# ble_rfcore_mdm_secure register map
Vendor: Texas Instruments
Registers are 32-bit, access per field, reset 0x0 unless marked. A register's access mark holds for its fields unless they carry their own. Offsets are as the file gives them; [hi:lo] are bit positions; {n}, {i} and the like mark numbered series; 'fields as' and 'values as' point back to an identical list.

## ble_rfcore_mdm_secure (part 2 of 2)
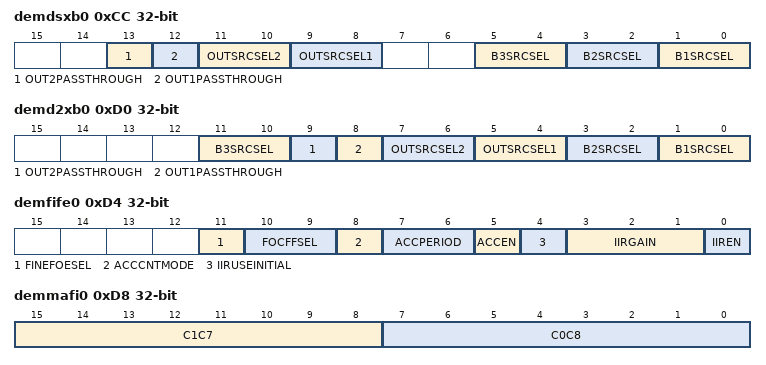
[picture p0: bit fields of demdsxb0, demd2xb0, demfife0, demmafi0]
0xCC demdsxb0 — Demodulator Decode Stage Crossbar Register 0
  [13] OUT2PASSTHROUGH rw — Crossbar output #2 is direct passthrough of the crossbar input
  [12] OUT1PASSTHROUGH rw — Crossbar output #1 is direct passthrough of the crossbar input
  [11:10] OUTSRCSEL2 rw — Source select XBAR output, branch 1 (baud branch)
    0=FIFE (Source is fine frequency offset estimator (FIFE)); 1=MAFI (Source is matched filter (MAFI)); 2=C1BE (Source is 1-bit correlation engine (C1BE))
  [9:8] OUTSRCSEL1 rw — Source select for XBAR output, branch 2 (flushed branch)
    values as OUTSRCSEL2
  [5:4] B3SRCSEL rw — Source select for C1BE (XBAR block #3)
    0=INPUT (Source is crossbar main input); 1=FIFE (Source is fine frequency offset estimator (FIFE)); 2=MAFI (Source is matched filter (MAFI))
  [3:2] B2SRCSEL rw — Source select for MAFI (XBAR block #2)
    0=INPUT (Source is crossbar main input); 1=FIFE (Source is fine frequency offset estimator (FIFE)); 2=C1BE (Source is 1-bit correlation engine (C1BE))
  [1:0] B1SRCSEL rw — Source select for FIFE (XBAR block #1)
    0=INPUT (Source is crossbar main input); 1=MAFI (Source is matched filter (MAFI)); 2=C1BE (Source is 1-bit correlation engine (C1BE))
0xD0 demd2xb0 — Demodulator Decode Stage Second Crossbar Register 0
  [11:10] B3SRCSEL rw — Source select for PDIF2 (XBAR block #3)
    0=INPUT (Source is crossbar main input); 1=MAFC (Source is manual frequency compensation (MAFC)); 2=STIM (Source is symbol timing (STIM))
  [9] OUT2PASSTHROUGH rw — Crossbar output #2 is direct passthrough of the crossbar input
  [8] OUT1PASSTHROUGH rw — Crossbar output #1 is direct passthrough of the crossbar input
  [7:6] OUTSRCSEL2 rw — Source select XBAR output, branch 1 (towards MLSE)
    0=MAFC (Source is manual frequency compensation (MAFC)); 1=STIM (Source is symbol timing (STIM)); 2=PDIF2 (Source is secondary PDIF module (PDIF2))
  [5:4] OUTSRCSEL1 rw — Source select for XBAR output, branch 2 (towards SOFD)
    values as OUTSRCSEL2
  [3:2] B2SRCSEL rw — Source select for STIM (XBAR block #2)
    0=INPUT (Source is crossbar main input); 1=MAFC (Source is manual frequency compensation (MAFC)); 2=PDIF2 (Source is secondary PDIF module (PDIF2))
  [1:0] B1SRCSEL rw — Source select for MAFC (XBAR block #1)
    0=INPUT (Source is crossbar main input); 1=STIM (Source is symbol timing (STIM)); 2=PDIF2 (Source is secondary PDIF module (PDIF2))
0xD4 demfife0 — Demodulator Fine Frequency Offset Estimator Register 0
  [11] FINEFOESEL rw — Select which estimator to show as readable output
    0=IIR (Latest IIR estimate); 1=ACC (Latest accumulator estimate)
  [10:9] FOCFFSEL rw — Select which estimate source to be used in feed-forward compensation point
    0=IIR (Compensate with latest IIR estimate); 1=ACC (Compensate with latest accumulator estimate); 2=MANUAL (Use programmable manual value from register bank. (Note: an input register is not implemented, so the manual compensation value is tied to '0'))
  [8] ACCCNTMODE rw — Accumulator estimator mode
    0=SINGLE (Generate a single frequency offset estimate only, then stop); 1=CONT (Generate new frequency offset estimates continuously)
  [7:6] ACCPERIOD rw — Integration period for accumulator
    0=PER64 (64 samples); 1=PER128 (128 samples); 2=PER256 (256 samples); 3=PER512 (512 samples)
  [5] ACCEN rw — Enable accumulator based frequency offset estimator inside FIFE
    0=DIS (Disable accumulator estimator); 1=EN (Enable accumulator estimator)
  [4] IIRUSEINITIAL rw — When enabled, a configurable value is loaded to initialize IIR filter when FIFE estimator is re-initialized.
    0=DIS (Initialize IIR filter with value zero); 1=EN (Use the manual compensation value in DEMFIFE1 for initialization)
  [3:1] IIRGAIN rw — Adjust first-order IIR filter adaptation which controls filter bandwidth
    0=OFF (Filter disabled); 1=DIV16 (Use 1/16 IIR adaptation); 2=DIV32 (Use 1/32 IIR adaptation); 3=DIV64 (Use 1/64 IIR adaptation); 4=DIV128 (Use 1/128 IIR adaptation); 5=DIV256 (Use 1/256 IIR adaptation); 6=DIV512 (Use 1/512 IIR adaptation); 7=DIV1024 (Use 1/1024 IIR adaptation)
  [0] IIREN rw — Enable first-order IIR filter based freq offset estimator inside FIFE
    0=DIS (Disable IIR estimator); 1=EN (Enable IIR estimator)
0xD8 demmafi0 — Demodulator Matched Filter Register 0
  [15:8] C1C7 rw — Filter coefficient c1 (and c7)
  [7:0] C0C8 rw — Filter coefficient c0 (and c8)
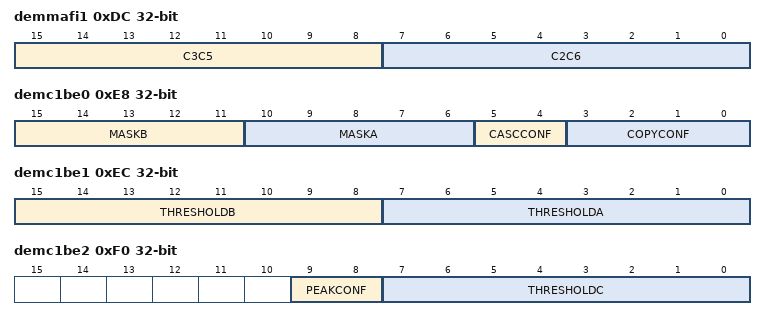
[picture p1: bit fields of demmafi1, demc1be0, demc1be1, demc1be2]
0xDC demmafi1 — Demodulator Matched Filter Register 1
  [15:8] C3C5 rw — Filter coefficient c3 (and c5)
  [7:0] C2C6 rw — Filter coefficient c2 (and c6)
0xE0 demmafi2 — Demodulator Matched Filter Register 2
  [8:0] C4 rw — Filter coefficient c4. The matched filter will have unity gain when the sum of all coefficients c0 to c8 equals 512.
0xE4 demmafi3 — Demodulator Matched Filter Register 3
  [8:0] K rw — Output level adjustment. Adjusting LSB of k will adjust LSB of matched filter output accordingly.
0xE8 demc1be0 — Demodulator Correlator 1-bit Engine Register 0
  [15:11] MASKB rw — Mask for correlator B to select the correlator length to use. The number specifies number of nibbles (i.e. 4-bit block, which typically corresponds to one symbol) of the correlator holding the oldest samples that will be ignored in computations. When set to zero, the full 128 sample (=32 symbol) correlator length will be used.
  [10:6] MASKA rw — Mask for correlator A to select the correlator length to use. The number specifies number of nibbles (i.e. 4-bit block, which typically corresponds to one symbol) of the correlator holding the oldest samples that will be ignored in computations. When set to zero, the full 128 sample (=32 symbol) correlator length will be used.
  [5:4] CASCCONF rw — Correlator cascade configuration
    0=SINGLE (Correlator B not used); 1=SERIAL (Connect correlators in series (A -> B)); 2=PARALLEL (Connect correlators in parallel)
  [3:0] COPYCONF rw — Control auto copy of contents from corr A to corr B
0xEC demc1be1 — Demodulator Correlator 1-bit Engine Register 1
  [15:8] THRESHOLDB rw — Correlation threshold value for correlator B
  [7:0] THRESHOLDA rw — Correlation threshold value for correlator A
0xF0 demc1be2 — Demodulator Correlator 1-bit Engine Register 2
  [9:8] PEAKCONF rw — Configuration to control peak event generation (applies to correlators A, B, D, E)
    0=THRESH (Trigger peak event on all peaks above threshold); 1=BEST (Trigger peak event only if peak is highest in correlator since search start); 2=BESTAB (Trigger peak event for combined highest peak search for corr "A and B" and "D and E" in pairs)
  [7:0] THRESHOLDC rw — Correlation threshold value for correlator C (corr C is A+B concatenated)
0xF4 demc1be10 — Demodulator Correlator 1-bit Engine Control
  [14:13] PEAKCONF_C rw — Configuration to control peak event generation for correlator C
    0=THRESH (Trigger peak event on all peaks above threshold); 1=BEST (Trigger peak event only if peak is highest in correlator since search start); 2=BESTAB (Trigger peak event for combined highest peak search for corr C and F)
0xF8 mdmsync0 — Modem Sync Word Register 0
  [15:0] SWA15C0 rw — Sync word A bits 15:0. Sync words shorter than 32 bits must be stored as most signicant bits of sync word A. The sync word is expected to be transmitted/received in lsb to msb order.
0xFC mdmsync1 — Modem Sync Word Register 1
  [15:0] SWA31C16 rw — Sync word A bits 31:16. Sync words shorter than 32 bits must be stored as most significant bits of sync word A. The sync word is expected to be transmitted/received in lsb to msb order.
0x100 mdmsync2 — Modem Sync Word Register 2
  [15:0] SWB15C0 rw — Sync word B bits 15:0. Sync words shorter than 32 bits must be stored as most significant bits of sync word B. The sync word is expected to be transmitted/received in lsb to msb order.
0x104 mdmsync3 — Modem Sync Word Register 3
  [15:0] SWB31C16 rw — Sync word B bits 31:16. Sync words shorter than 32 bits must be stored as most significant bits of sync word B. The sync word is expected to be transmitted/received in lsb to msb order.
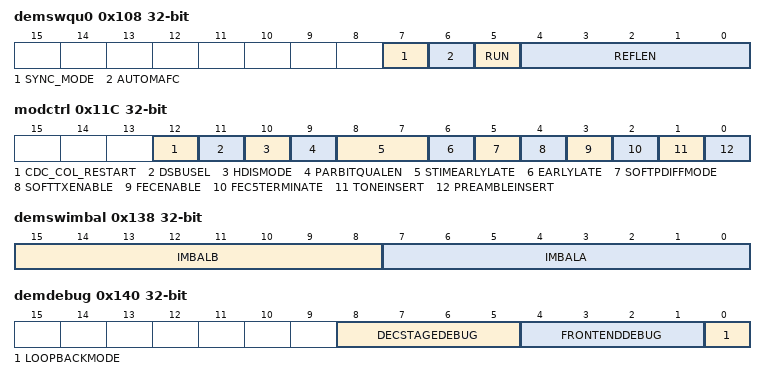
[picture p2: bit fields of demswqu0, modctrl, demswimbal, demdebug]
0x108 demswqu0 — Demodulator Sync Word Qualifier Register 0
  [7] SYNC_MODE rw — 0: Search for A and B in parallell
  [6] AUTOMAFC rw — Let sync word qualifier automatically control the manual frequency offset compensation (MAFC) block when it is running
    0=DIS (Keep manual control over MAFC); 1=EN (Give control to sync word qualifier)
  [5] RUN rw — Start/stop sync word qualifier
  [4:0] REFLEN rw — Bit length of sync word qualifier reference vector, constituted by (reflen + 1) most significant bits of sync word A and/or B.
0x10C demc1beref0 — Correlator reference register 0
  [15:0] CAR15C0 rw — Corr A reference bits 15:0.
0x110 demc1beref1 — Correlator reference register 1
  [15:0] CAR31C16 rw — Corr A reference bits 31:16
0x114 demc1beref2 — Correlator reference register 2
  [15:0] CBR15C0 rw — Corr B reference bits 15:0.
0x118 demc1beref3 — Correlator reference register 3
  [15:0] CBR31C16 rw — Corr B reference bits 31:16
0x11C modctrl — Dynamic Modem Control Signals from MCE
  [12] CDC_COL_RESTART rw — Collision restart for CDC FIFO
  [11] DSBUSEL rw — Select DSBU input source
  [10] HDISMODE rw — Enable Hilbert discriminator mode for data descicion
  [9] PARBITQUALEN rw — Enable Parallel Bit Qualifier (read DEMC1BEA)
  [8:7] STIMEARLYLATE rw — Controls STIM module for early/late modes
    0=NORMAL (Normal Mode); 1=LATE (STIM starts late); 2=EARLY (STIM starts early)
  [6] EARLYLATE rw — Set the C1BE in special early/late mode
  [5] SOFTPDIFFMODE rw — Enable Soft PDIFF mode for RX
  [4] SOFTTXENABLE rw — Enable SOFT TX mode, controlled via MODSOFTTX
  [3] FECENABLE rw — Global FEC modes enable
  [2] FEC5TERMINATE rw — Goes into termination mode in 5Mbps TX FEC
  [1] TONEINSERT rw — Inserts a tone
  [0] PREAMBLEINSERT rw — Inserts preamble
0x120 modpreamble — Dynamic Modulator Preamble Register
  [15:0] WORD rw — 16 bit preamble word pattern. The LSB is transmitted first.
0x124 demfidc1 — Demodulator Fine DC Offset Estimator Register 1
  [12:0] COMPIVAL rw — Compensation value for I path
0x128 demfidc2 — Demodulator Fine DC Offset Estimator Register 2
  [12:0] COMPQVAL rw — Compensation value for Q path
0x12C demfife1 — Demodulator Fine Frequency Offset Estimator Register 1
  [7:0] FOCFBREGVAL rw — Value for feed-back compensation point (signed)
0x130 demmafc0 — Demodulator Manual Frequency Compensation Register 0
  [7:0] COMPVAL rw — Value for manual compensation (signed)
0x134 demmafi4 — Demodulator Matched Filter Register 4
  [7:0] TERM_VAL rw — Input value to terminate matched filter with. Writing to this register triggers the termination.
0x138 demswimbal — Demodulator Sync Word DC Imbalance Register
  [15:8] IMBALB rw — DC imbalance in sync word B, applied via SWQU upon C1BE correlator A peak event
  [7:0] IMBALA rw — DC imbalance in sync word A, applied via SWQU upon C1BE correlator B peak event
0x13C demsoftpdiff — Demodulator Soft PDIFF Value Register
  [7:0] SOFTPDIFF rw — Replaces PDIFF output when in Soft PDIFF Mode. Can be used for manually feeding samples (e.g. on-off-keying (OOK) samples from RFE) into the demodulator decode stage.
0x140 demdebug — Demodulator Debug Register
  [8:5] DECSTAGEDEBUG rw — Selects which decode stage signal source to dump for debugging via S2R module. The decode stage samples are signed 8-bit samples, packed into 32-bit words with the oldest sample as the most significant byte.
    0=NOSEL (No source selected); 1=PDIF (Dump PDIF output samples); 2=MAFI (Dump MAFI output samples); 3=STIM (Dump STIM output samples); 4=MAFC (Dump MAFC output samples); 5=C1BE (Dump C1BE correlator A value (truncated to 8 LSBs only, may overflow if correlator value is +128).); 6=SOFD (Dump SOFD output samples); 8=TRIGGER (The most significant bit is used as manual event trigger to start a new sample capture via S2R module when RFC_S2R:S2RCFG.TRIGGERMODE is set to trigger-on-event and the S2R module has been armed via RFC_S2R:S2RCFG.TRIGGER bit.)
  [4:1] FRONTENDDEBUG rw — Selects which front-end stage signal source to dump for AoA via DEM-S2R module. The front-end stage samples are signed 16-bit samples from both I and Q signal path, packed together into 32-bit words with the I sample as the 16 MSB and Q sample as the 16 LSB. 0000 : NOSEL : No source selected 0001 : BDE2 : Dump BDE2 output samples 0010 : CHFI : Dump CHFI output samples 0011 : FIDC : Dump FIDC output samples
    0=NOSEL (No source selected); 1=FELP (Dump FELP output samples); 2=IQMC (Dump IQMC output samples); 3=BDE1 (Dump BDE1 output samples); 4=FEXB2 (Dump FEXB output #2 samples, as selected by DEMFEXB0.OUT2SRCSEL register); 5=BDE2 (Dump BDE2 output samples); 6=CHFI (Dump CHFI output samples); 7=FRAC (Dump FRAC output samples); 8=TRIGGER (The most significant bit is used as manual event trigger to start a new sample capture via S2R module when RFC_S2R:S2RCFG.TRIGGERMODE is set to trigger-on-event and the S2R module has been armed via RFC_S2R:S2RCFG.TRIGGER bit.)
  [0] LOOPBACKMODE rw — Enables loopback mode
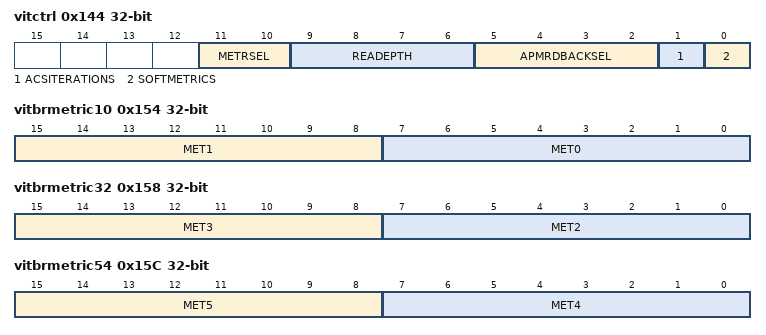
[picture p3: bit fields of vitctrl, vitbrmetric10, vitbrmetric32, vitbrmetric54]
0x144 vitctrl — Viterbi Control Register
  [11:10] METRSEL rw — Selects which HW module is connected to viterbi decoder
    0=MET5M (Use 5Mbps Metrics); 1=PHAC (Use PHAC Metrics); 2=SOFD (Use SOFD Metrics); 3=MLSE (Use MLSE Metrics)
  [9:6] READEPTH rw — Depth of the REA algorithm
  [5:2] APMRDBACKSEL rw — Selects the APM to read back via VITAPMRDBACK register
    0=NOSEL (No selection); {v}=APM{v-8} (View APM {v-8}) (v=8..15)
  [1] ACSITERATIONS rw — Number of iterations per ACS element
    0=CODE12 (2 iterations per ACS (2 branches, 1/2 codes)); 1=CODE23 (4 iterations per ACS (4 branches, 2/3 codes))
  [0] SOFTMETRICS rw — Enable Soft Metrics
    0=HW (Use HW metrics as defined by [VITCTRL.metrsel] bits); 1=SOFT (Use soft Metrics (register based))
0x148 vitcompute — Viterbi Compute Register Register type is WI ("Write Impulse"): Write generate 1-clock cycle pulse, Read 0.
  [0] COMPUTE wo — Initiates a compute cycle
0x14C vitapmrdback ro — Viterbi APM Readback Register
  [9:0] VALUE — APM for element i (selected in VITCTRL register)
0x150 vitstate ro — Viterbi State Register
  [2:0] VALUE — Current Winning State
0x154 vitbrmetric10 — Viterbi Branch Metric 1 and 0 Register
  [15:8] MET1 rw — Branch Metric 1
  [7:0] MET0 rw — Branch Metric 0
0x158 vitbrmetric32 — Viterbi Branch Metric 3 and 2 Register
  [15:8] MET3 rw — Branch Metric 3
  [7:0] MET2 rw — Branch Metric 2
0x15C vitbrmetric54 — Viterbi Branch Metric 5 and 4 Register
  [15:8] MET5 rw — Branch Metric 5
  [7:0] MET4 rw — Branch Metric 4
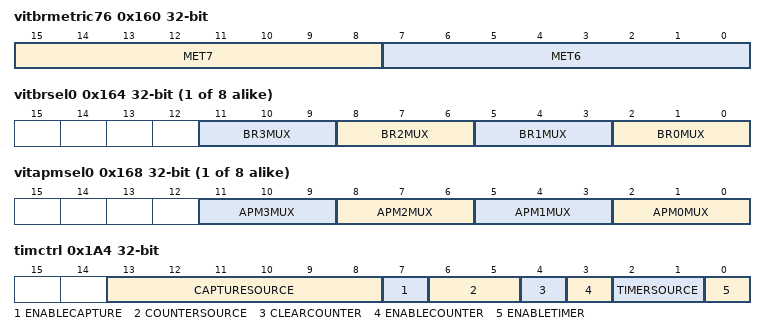
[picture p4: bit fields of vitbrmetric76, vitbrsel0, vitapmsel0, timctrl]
0x160 vitbrmetric76 — Viterbi Branch Metric 7 and 6 Register
  [15:8] MET7 rw — Branch Metric 7
  [7:0] MET6 rw — Branch Metric 6
{0x164+8i} vitbrsel{i} (i=0..7) — Viterbi Branch Select Register {i}
  [3n+2:3n] BR{n}MUX rw (n=0..3) — ACS Element {i}, Branch Metric Mux {n}
{0x168+8i} vitapmsel{i} (i=0..7) — Viterbi APM Select Register {i}
  [3n+2:3n] APM{n}MUX rw (n=0..3) — ACS Element {i}, Accumulated Path Metric Mux {n}
0x1A4 timctrl — Modem Timer and Counter Control Register
  [13:8] CAPTURESOURCE rw — Selects bit number from event bus for a counter capture. Event number in range 0 to 63.
  [7] ENABLECAPTURE rw — Enable counter capture on event. Upon a capture event, the counter value will be captured in TIMCAPT register.
    0=DIS (Disable capture mode for counter); 1=EN (Enable capture mode for counter)
  [6:5] COUNTERSOURCE rw — Select event source for counter
    0=CLK (Use clock); 1=CLKBAUD (Use baud event); 2=CLK4BAUD (Use 4xBaud event); 3=CLK4BAUDF (Use 4xBaud flushed event)
  [4] CLEARCOUNTER rw — Clear counter value in TIMCOUNTER to zero when this bit is set to 1.
  [3] ENABLECOUNTER rw — Enable 16-bit counter when set to 1. The counter will continue from its current value.
  [2:1] TIMERSOURCE rw — Select timer tick source for timer
    0=CLK (Clock); 1=CLKBAUD (Baud); 2=CLK4BAUD (4xBaud); 3=CLK4BAUDF (4xBaud flushed)
  [0] ENABLETIMER rw — Enable 16-bit timer. It will generate a timer interrupt after TIMPERIOD timer ticks. Note that the internal timer value is not readable from the MCE. If this is needed the counter should be used instead of the timer.
    0=DIS (Will disable timer and clear internal timer value); 1=EN (Will enable timer)
0x1A8 timinc — Modem Counter Increment Configuration
  [15:0] INCUNIT rw — Programmable counter increment. For each counter event: TIMCOUNTER = TIMCOUNTER + (TIMINC.INCUNIT + 1).
0x1AC timperiod — Modem Timer/Counter Period Configuration
  [15:0] PERIOD rw — Configurable 16 bit period that can be used for either the timer or the counter. In timer context, when timer value reach the timer period (i.e. it expires) a TIMER_IRQ event will occur, and the timer will restart from zero (until the timer is manually disabled). In counter context, a COUNTER_IRQ event will occur when the counter is equal to or higher than the period value.
0x1B0 timcounter ro — Modem Counter Value
  [15:0] VALUE — 16 bit counter value that can be read by the MCE.
0x1B4 timcapt ro — Modem Counter Capture Value
  [15:0] VALUE — Captured value of counter
0x1B8 timebase — Modem Timebase Control Register Register type is WI ("Write Impulse"): Write generate 1-clock cycle pulse, Read 0.
  [0] FLUSH wo — Starts a flushing process
0x1BC count1in — Local Count Ones Input Register
  [15:0] VAL rw — Input data, which we shall find the number of 1's in
0x1C0 count1res ro — Local Count Ones Result Register
  [4:0] COUNT — Number of 1's in the COUNT1IN register
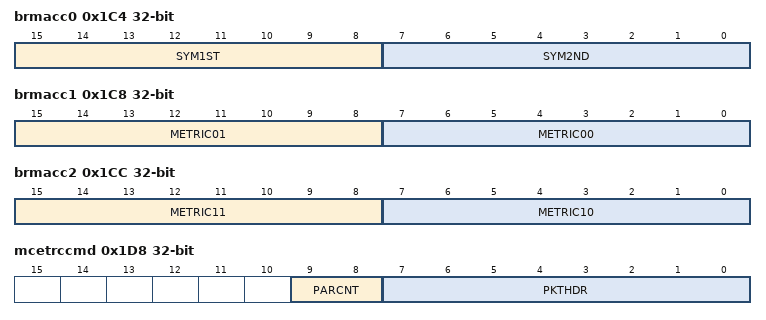
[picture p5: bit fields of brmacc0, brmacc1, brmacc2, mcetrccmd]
0x1C4 brmacc0 — Local Branch Metric Accelerator Register 0
  [15:8] SYM1ST rw — Symbol 1st (first, left one). Soft input symbol for calculating branch metrics of 1/2 rate codes. A saturated value of +/- 60 will be used in the calculations if the soft symbol exceeds this range.
  [7:0] SYM2ND rw — Symbol 2nd (last, right one). Soft input symbol for calculating branch metrics of 1/2 rate codes. A saturated value of +/- 60 will be used in the calculations if the soft symbol exceeds this range.
0x1C8 brmacc1 ro — Local Branch Metric Accelerator Module Register 1
  [15:8] METRIC01 — Metric to 01 (-1 +1) symbol. Immediately calculated when BRMACC0 register is written.
  [7:0] METRIC00 — Metric to 00 (-1 -1) symbol. Immediately calculated when BRMACC0 register is written.
0x1CC brmacc2 ro — Local Branch Metric Accelerator Module Register 2
  [15:8] METRIC11 — Metric to 11 (+1 +1) symbol. Immediately calculated when BRMACC0 register is written.
  [7:0] METRIC10 — Metric to 10 (+1 -1) symbol. Immediately calculated when BRMACC0 register is written.
0x1D0 mcetrcsend — MCE Tracer Send Trigger Register Register type is WI ("Write Impulse"): Write generate 1-clock cycle pulse, Read 0.
  [0] SEND wo — Sends a command to the tracer
0x1D4 mcetrcbusy ro — MCE Tracer Status Register
  [0] BUSY — Checks if the tracer is busy
0x1D8 mcetrccmd — MCE Tracer Command Register
  [9:8] PARCNT rw — Number of parameters
  [7:0] PKTHDR rw — Packet header
0x1DC mcetrcpar0 — MCE Tracer Command Parameter Register 0
  [15:0] PAR0 rw — Parameter 0
0x1E0 mcetrcpar1 — MCE Tracer Command Parameter Register 1
  [15:0] PAR1 rw — Parameter 1
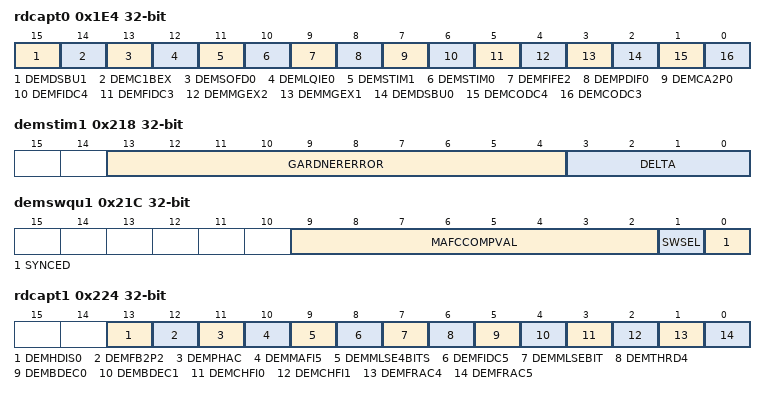
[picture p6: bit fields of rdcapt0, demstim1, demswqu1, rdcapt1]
0x1E4 rdcapt0 — Modem Readback Capture Register - Each bit Capture a specific signal. Register type is WI ("Write Impulse"): Write generate 1-clock cycle pulse, Read 0.
  [15] DEMDSBU1 wo — Capture read value into DEMDSBU1 RC register
  [14] DEMC1BEX wo — Capture read values into DEMC1BE3, DEMC1BE4, DEMC1BE5, DEMC1BE6, DEMC1BE7, DEMC1BE8, DEMC1BE9, and DEMC1BEA RC registers
  [13] DEMSOFD0 wo — Capture read value into DEMSOFD0 RC register
  [12] DEMLQIE0 wo — Capture read value into DEMLQIE0 RC register
  [11] DEMSTIM1 wo — Capture read value into DEMSTIM1 RC register
  [10] DEMSTIM0 wo — Capture read value into DEMSTIM0 RC register
  [9] DEMFIFE2 wo — Capture read value into DEMFIFE2 RC register
  [8] DEMPDIF0 wo — Capture read value into DEMPDIF0 RC register
  [7] DEMCA2P0 wo — Capture read value into DEMCA2P0 RC register
  [6] DEMFIDC4 wo — Capture read value into DEMFIDC4 RC register
  [5] DEMFIDC3 wo — Capture read value into DEMFIDC3 RC register
  [4] DEMMGEX2 wo — Capture read value into DEMMGEX2 RC register
  [3] DEMMGEX1 wo — Capture read value into DEMMGEX1 RC register
  [2] DEMDSBU0 wo — Capture read value into DEMDSBU0 RC register
  [1] DEMCODC4 wo — Capture read value into DEMCODC4 RC register
  [0] DEMCODC3 wo — Capture read value into DEMCODC3 RC register
0x1E8 demmgex1 ro — Demodulator Magnitude Estimator #1
  [12:0] MGE1ESTOUT — Magnitude estimate from estimator 1
0x1EC demfidc3 ro — Demodulator Fine DC Estimator Register 3
  [12:0] ESTOUTI — Fine DC estimate I channel
0x1F0 demfidc4 ro — Demodulator Fine DC Estimator Register 4
  [12:0] ESTOUTQ — Fine DC estimate Q channel
0x1F4 demca2p0 ro — Demodulator Cartesian To Polar Register 0
  [8:0] PHASE — Phase of current sample
0x1F8 dempdif0 ro — Demodulator Phase Differentiator Register 0
  [7:0] PDIFF — Instfreq of current samples
0x1FC demc1be3 ro — Demodulator Correlator 1-bit Engine Register 3
  [15:0] CORRVALUEA — Correlation calue correlator A
0x200 demc1be4 ro — Demodulator Correlator 1-bit Engine Register 4
  [15:0] CORRVALUEB — Correlation value correlator B
0x204 demc1be5 ro — Demodulator Correlator 1-bit Engine Register 5
  [15:0] CORRVALUEC — Correlation value combined correlator (corr C is corr A+B combined)
0x208 demfife2 ro — Demodulator Fine Frequency Offset Estimator Register 2
  [7:0] FINEFOCEST — Frequency offset estimate fine foc
0x20C demdsbu0 ro — Demodulator Dynamic Sample Buffer Register 0
  [8:0] RDPOUT — Current read pointer of DSBU
0x210 demdsbu1 ro — Demodulator Dynamic Sample Buffer Register 1
  [15:0] AVGVAL — Current sum of samples between write and read pointers
0x214 demstim0 ro — Demodulator Symbol Timing Register 0
  [5:0] EVENTS — Number of stall/advance events occured
0x218 demstim1 ro — Demodulator Symbol Timing Register 1
  [13:4] GARDNERERROR — Timing error
  [3:0] DELTA — Current fractional delay
0x21C demswqu1 ro — Demodulator Sync Word Qualifier Register 1
  [9:2] MAFCCOMPVAL — Frequency Offset value computed by SWQU
  [1] SWSEL — Shows which sync word had a peak event and was selected for sync word qualification test. This is to tell which sync word was detected when radio operates in receive mode with dual sync word search.
    0=A (The C1BE emitted a correlator A peak event and SWQU selected sync word A for qualification test (or no SWQU sync word test has been performed yet)); 1=B (The C1BE emitted a correlator B peak event and SWQU selected sync word B for qualification test)
  [0] SYNCED — Reads as '1' when the sync word specified by SWSEL has passed qualification, otherwise '0'. Note that the sync word qualification is only performed on MSB portion of the reference vector, as specified in DEMSWQU0.REFLEN register.
0x220 demsofd0 ro — Demodulator Soft Decision Register 0
  [7:0] SOFTSYMBOL — Soft symbol value
0x224 rdcapt1 — Modem Readback Capture Register 2 - Each bit Capture a specific signal. Register type is WI ("Write Impulse"): Write generate 1-clock cycle pulse, Read 0.
  [13] DEMHDIS0 wo — Capture read value into DEMHDIS0 register
  [12] DEMFB2P2 wo — Capture read value into DEMFB2P2 registers
  [11] DEMPHAC wo — Capture read value into DEMPHAC8 and DEMPHAC9 registers
  [10] DEMMAFI5 wo — Capture read value into DEMAFI5 RC register
  [9] DEMMLSE4BITS wo — Capture read value into DEMMLSE4BITS RC register
  [8] DEMFIDC5 wo — Capture read value into DEMFIDC5 RC register
  [7] DEMMLSEBIT wo — Capture read value into DEMMLSEBIT RC register
  [6] DEMTHRD4 wo — Capture read value into DEMTHRD4 RC register
  [5] DEMBDEC0 wo — Capture read value into DEMBDEC0 RC register
  [4] DEMBDEC1 wo — Capture read value into DEMBDEC1 RC register
  [3] DEMCHFI0 wo — Capture read value into DEMCHFI0 RC register
  [2] DEMCHFI1 wo — Capture read value into DEMCHFI1 RC register
  [1] DEMFRAC4 wo — Capture read value into DEMFRAC4 RC register
  [0] DEMFRAC5 wo — Capture read value into DEMFRAC5 RC register
0x228 demmlsebit ro — Demodulator Maximum Likelihood Sequence Estimation Register
  [0] MLSEBIT — MLSE decoded output bit
0x22C dembdec0 ro — I signal after the BDEC module
  [12:0] IVAL — 13-bit I value
0x230 dembdec1 ro — Q signal after the BDEC module
  [12:0] QVAL — 13-bit Q value
0x234 demchfi0 ro — I signal after the CHFI module
  [12:0] IVAL — 13-bit I value
0x238 demchfi1 ro — Q signal after the CHFI module
  [12:0] QVAL — 13-bit Q value
0x23C demfidc5 ro — Output of Fine DC (FIDC) Filter module
  [12:0] IVAL — 13-bit I value
0x240 demmafi5 ro — Output of Matched Filter (MAFI)
  [7:0] MAFIOUT — 8-bit signed value
0x244 demc1be6 ro — Demodulator Correlator 1-bit Engine Register 6
  [7:0] VAL — A Correlation Peak x[n-1] Sample
0x248 demc1be7 ro — Demodulator Correlator 1-bit Engine Register 7
  [7:0] VAL — A Correlation Peak x[n+1] Sample
0x24C demc1be8 ro — Demodulator Correlator 1-bit Engine Register 8
  [7:0] VAL — B Correlation Peak x[n-1] Sample
0x250 demc1be9 ro — Demodulator Correlator 1-bit Engine Register 9
  [7:0] VAL — B Correlation Peak x[n+1] Sample
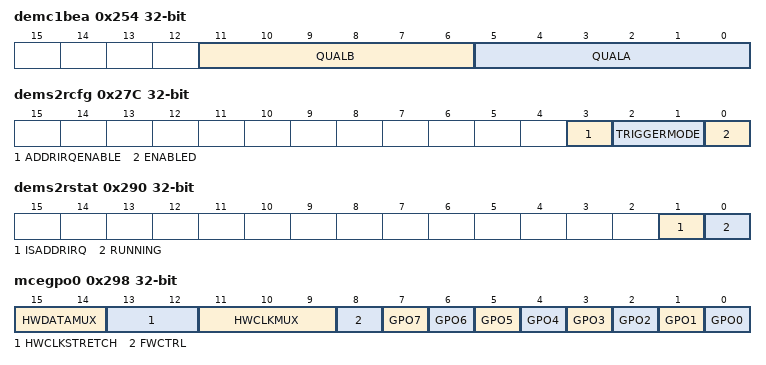
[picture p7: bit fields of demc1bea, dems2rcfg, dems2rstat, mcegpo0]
0x254 demc1bea ro — Demodulator Correlator 1-bit Engine Register A
  [11:6] QUALB — Parallel Bit Qualifier for Correlator B
  [5:0] QUALA — Parallel Bit Qualifier for Correlator A
{0x258+4i} mdmspar{i} (i=0..3) — Modem Spare {i}
  [15:0] VAL rw — Spare register for use by firmware
0x268 demsofd1 ro — Soft Decision 4x Samples
  [7:0] SOFTX0 — Soft x[0] (newest sample)
0x26C demsofd2 ro — Soft Decision 4x Samples
  [7:0] SOFTX1 — Soft x[1] (center left sample)
0x270 demsofd3 ro — Soft Decision 4x Samples
  [7:0] SOFTX2 — Soft x[2] (center right sample)
0x274 demsofd4 ro — Soft Decision 4x Samples
  [7:0] SOFTX3 — Soft x[3] (oldest sample)
0x278 demdsbu3 ro — Demodulator Dynamic Sample Buffer Register 0
  [8:0] WRPOUT — Current write pointer of DSBU
0x27C dems2rcfg — DEC-S2R Main CFG Register
  [3] ADDRIRQENABLE rw — DEC-S2R - Enable for IRQ when ADDR Counter Is on SPECIFIC ADDR (dems2raddrirq)
  [2:1] TRIGGERMODE rw — DEC-S2R Trigger mode: 00 : ONESHOT : One shot mode, i.e. fill memory area once, from start to stop address, upon a manual trigger. 01 : PERIODIC : Periodic mode, i.e. fill memory area periodically, continuing at the start address after reaching the stop address, upon a manual trigger. 10 : ONEVENT : Trigger on event, i.e. fill memory area once, but wait for an event from the selected sample source. 11 : RESERVED : Reserved
  [0] ENABLED rw — DEMS2R module enable (Connect to the RAM-Sel Mux in destination).
0x280 dems2rtrigger — DEC-S2R Trigger Register
  [0] TRIGGER wo — TDEC-S2R Trigger a new sample capture. (or arm it if the trigger mode is trigger on event)
0x284 dems2raddrstart — DEC-S2R Start Addr Register
  [15:0] ADDRSTART rw — DEC-S2R - Memory start address for where to dump the samples.
0x288 dems2raddrstop — DEC-S2R Stop Addr Register
  [15:0] ADDRSTOP rw — DEC-S2R - Memory stop address for where to dump the samples.
0x28C dems2raddrirq — DEC-S2R Addr IRQ Register
  [15:0] ADDRIRQ rw — DEC-S2R - ADDR Pointer for generate IRQ when the ADDR Counter Is on This SPECIFIC ADDR (when dems2raddrirqenable)
0x290 dems2rstat ro — DEC-S2R Status Register
  [1] ISADDRIRQ — DEMS2R - ADDR Counter Is Now on ADDR IRQ (send Event to MCE/CPE)
  [0] RUNNING — DEC-S2R running status
0x294 dems2raddrcnt ro reset 0xFFFF — DEC-S2R Addr CNT Status Register
  [15:0] ADDRCNT — DEMS2R Current address counter value
0x298 mcegpo0 — Control of the MCE GPO signals
  [15:14] HWDATAMUX rw — Configure data mux
  [13:12] HWCLKSTRETCH rw — Configure clock stretch
  [11:9] HWCLKMUX rw — Configure clock mux
  [8] FWCTRL rw — Enable firmware control of MCE_GPO signals.
  [7] GPO7 rw — Direct MCE/FW control of MCE_GPO(7)
  [6] GPO6 rw — Direct MCE/FW control of MCE_GPO(6)
  [5] GPO5 rw — Direct MCE/FW control of MCE_GPO(5)
  [4] GPO4 rw — Direct FW/MCE control of MCE_GPO(4)
  [3] GPO3 rw — Direct control of MCE_GPO(3) when [MCEGPO0.fwctrl] = 1, otherwise Demodulator Output Word pulse
  [2] GPO2 rw — Direct control of MCE_GPO(2) when [MCEGPO0.fwctrl] = 1, otherwise Demodulator Output Word bit
  [1] GPO1 rw — Direct control of MCE_GPO(1) when [MCEGPO0.fwctrl] = 1, otherwise Demodulator Transparent Output bit
  [0] GPO0 rw — Direct control of MCE_GPO(0) when [MCEGPO0.fwctrl] = 1, otherwise Modulator Output Symbol Sign
0x29C mcepcstat ro — MCE TOPSM_PC Status Register
  [9:0] TOPSM_PC_STAT — Current MCE TOP-SM PC address value
